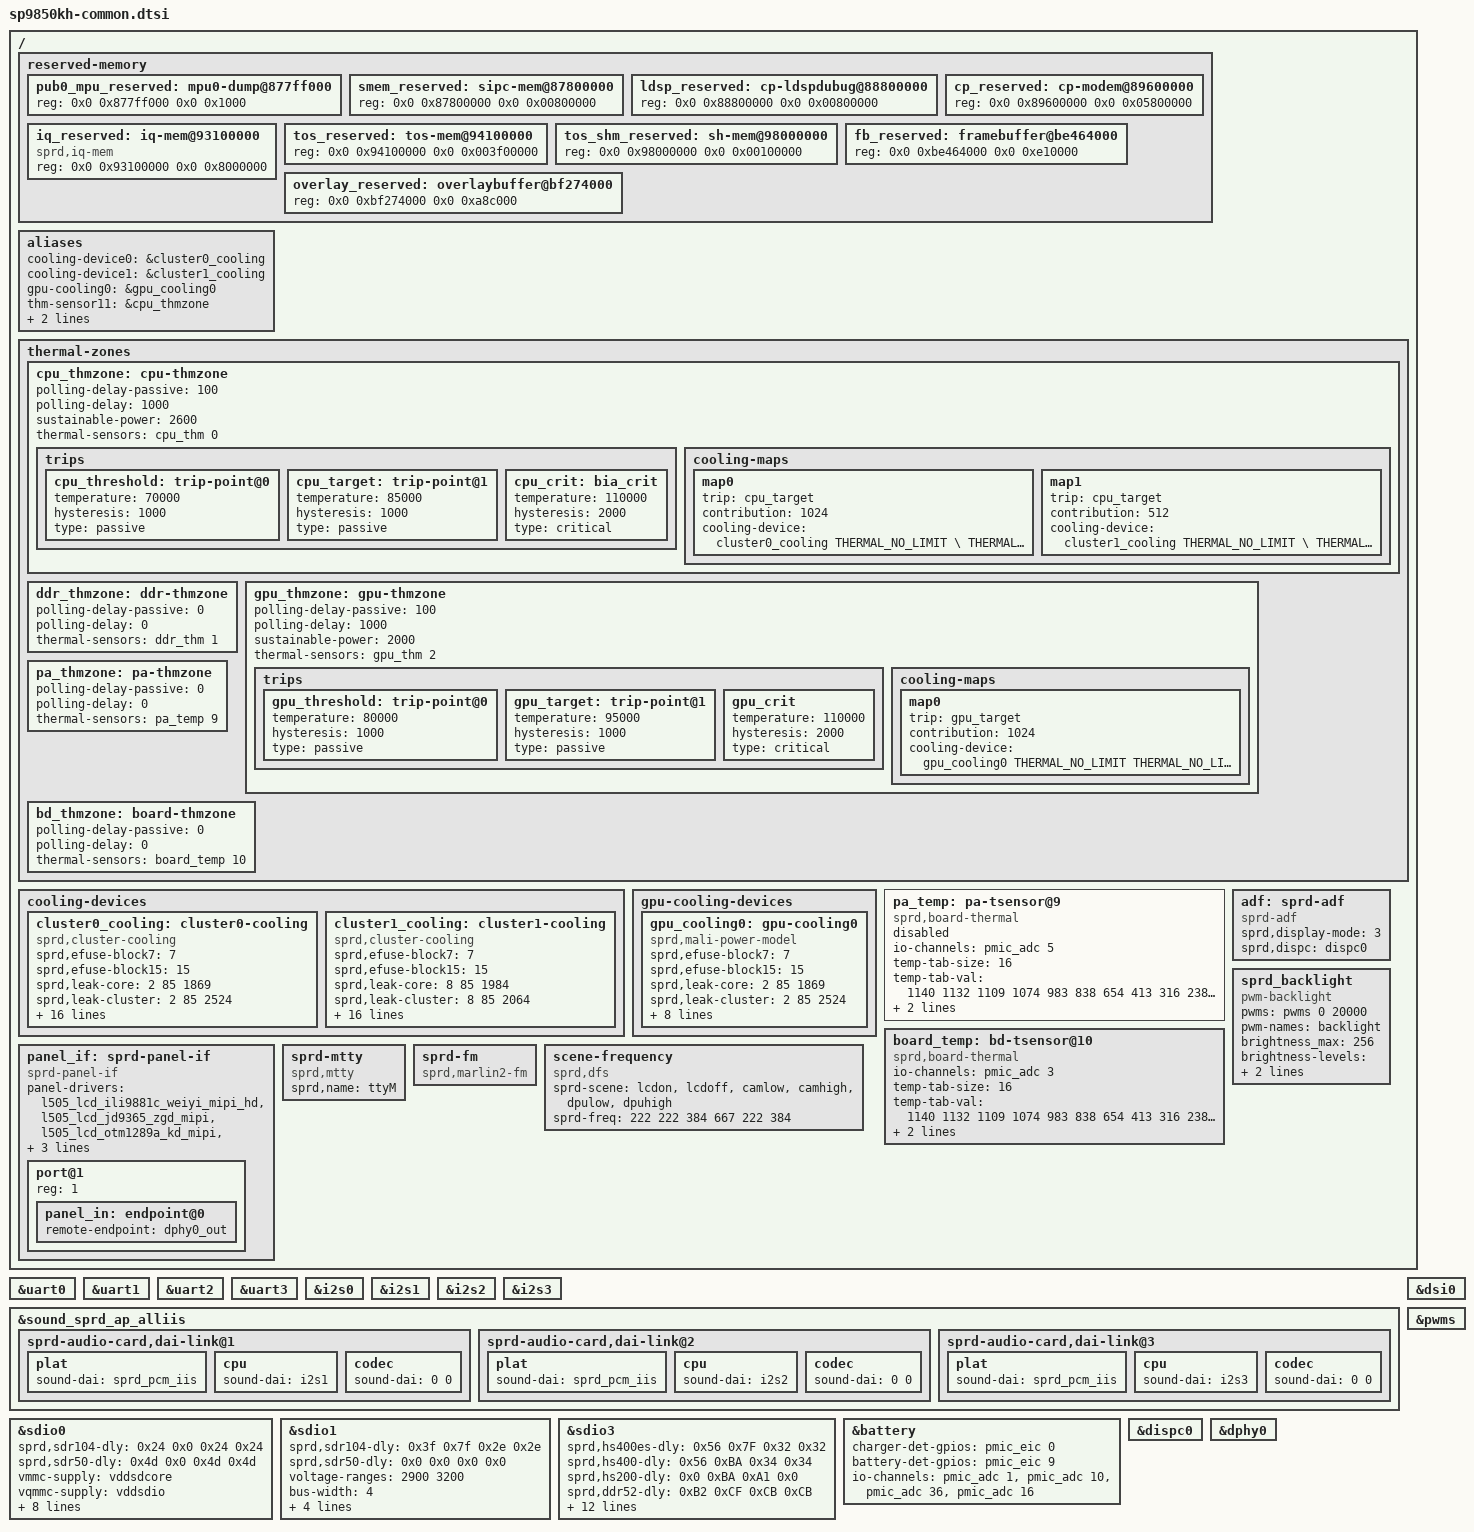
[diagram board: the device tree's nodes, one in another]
/*
 * Spreadtrum SP9850KH board common DTS file
 *
 * Copyright (C) 2016, Spreadtrum Communications Inc.
 *
 * This file is licensed under a dual GPLv2 or X11 license.
 */
#include "lcd/lcd_nt35597_mipi_2k_fpga.dtsi"
#include "lcd/lcd_ili9881c_mipi_hd.dtsi"
#include "lcd/lcd_dummy_rgb.dtsi"
#include "lcd/l505_lcd_ili9881c_weiyi_mipi_hd.dtsi"
#include "lcd/l505_lcd_jd9365_hf_mipi.dtsi"
#include "lcd/l505_lcd_jd9365_zgd_mipi.dtsi"
#include "lcd/l505_lcd_otm1289a_kd_mipi.dtsi"
#include "sc2721.dtsi"
#include "sprd-battery.dtsi"
#include "sp9850kh-modem.dtsi"
#include <dt-bindings/thermal/thermal.h>
#include "sprd-sound-sharkl.dtsi"

/ {
	reserved-memory {
		#address-cells = <2>;
		#size-cells = <2>;
		ranges;

		pub0_mpu_reserved: mpu0-dump@877ff000 {
			reg = <0x0 0x877ff000 0x0 0x1000>;
		};

		smem_reserved: sipc-mem@87800000{
			reg = <0x0 0x87800000 0x0 0x00800000>;
		};

		ldsp_reserved: cp-ldspdubug@88800000 {
			reg = <0x0 0x88800000 0x0 0x00800000>;
		};

		cp_reserved: cp-modem@89600000 {
			reg = <0x0 0x89600000 0x0 0x05800000>;
		};

		/* Only used for iq, will be removed in normal mode by uboot */
		iq_reserved: iq-mem@93100000{
			compatible = "sprd,iq-mem";
			reg = <0x0 0x93100000 0x0 0x8000000>;
		};

		tos_reserved: tos-mem@94100000{
		reg = <0x0 0x94100000 0x0 0x003f00000>;
		};

		tos_shm_reserved: sh-mem@98000000{
			reg = <0x0 0x98000000 0x0 0x00100000>;
		};

		fb_reserved: framebuffer@be464000{
			reg = <0x0 0xbe464000 0x0 0xe10000>;
		};

		overlay_reserved: overlaybuffer@bf274000{
			reg = <0x0 0xbf274000 0x0 0xa8c000>;
		};
	};

	aliases {
		cooling-device0 = &cluster0_cooling;
		cooling-device1 = &cluster1_cooling;
		gpu-cooling0 = &gpu_cooling0;
		thm-sensor11 = &cpu_thmzone;
		thm-sensor9 = &pa_temp;
		thm-sensor10 = &board_temp;
	};

	thermal-zones {

		cpu_thmzone: cpu-thmzone {
			polling-delay-passive = <100>;
			polling-delay = <1000>;
			sustainable-power = <2600>;
			thermal-sensors = <&cpu_thm  0>;
			trips {
				cpu_threshold: trip-point@0 {
					temperature = <70000>;
					hysteresis = <1000>;
					type = "passive";
				};
				cpu_target: trip-point@1 {
					temperature = <85000>;
					hysteresis = <1000>;
					type = "passive";
				};
				cpu_crit: bia_crit {
					temperature = <110000>;
					hysteresis = <2000>;
					type = "critical";
				};
			};
			cooling-maps {
				map0 {
					trip = <&cpu_target>;
					contribution = <1024>;
					cooling-device =
					<&cluster0_cooling THERMAL_NO_LIMIT \
					THERMAL_NO_LIMIT>;
				};
				map1 {
					trip = <&cpu_target>;
					contribution = <512>;
					cooling-device =
					<&cluster1_cooling THERMAL_NO_LIMIT \
					THERMAL_NO_LIMIT>;
				};
			};
		};

		ddr_thmzone: ddr-thmzone {
			polling-delay-passive = <0>;
			polling-delay = <0>;
			thermal-sensors = <&ddr_thm  1>;
		};

		gpu_thmzone: gpu-thmzone {
			polling-delay-passive = <100>;
			polling-delay = <1000>;
			sustainable-power = <2000>;
			thermal-sensors = <&gpu_thm  2>;
			trips {
				gpu_threshold: trip-point@0 {
					temperature = <80000>;
					hysteresis = <1000>;
					type = "passive";
				};
				gpu_target: trip-point@1 {
					temperature = <95000>;
					hysteresis = <1000>;
					type = "passive";
				};
				gpu_crit: gpu_crit {
					temperature = <110000>;
					hysteresis = <2000>;
					type = "critical";
				};
			};
			cooling-maps {
				map0 {
					trip = <&gpu_target>;
					contribution = <1024>;
					cooling-device =
					<&gpu_cooling0
						THERMAL_NO_LIMIT
						THERMAL_NO_LIMIT>;
				};
			};
		};

		pa_thmzone: pa-thmzone {
			polling-delay-passive = <0>;
			polling-delay = <0>;
			thermal-sensors = <&pa_temp  9>;
		};

		bd_thmzone: board-thmzone {
			polling-delay-passive = <0>;
			polling-delay = <0>;
			thermal-sensors = <&board_temp  10>;
		};
	};

	cooling-devices {
		cluster0_cooling: cluster0-cooling {
			compatible = "sprd,cluster-cooling";
			#cooling-cells = <2>; /* min followed by max */
			sprd,efuse-block7 = <7>;
			sprd,efuse-block15 = <15>;
			/* core_leak =                             */
			/*(LIT_LEAK[4:0]+1) x 2mA x 0.85V x 18.69% */
			sprd,leak-core = <2 85 1869>;
			/* cluster_leak =                           */
			/* (LIT_LEAK[4:0]+1) x 2mA x 0.85V x 25.24% */
			sprd,leak-cluster = <2 85 2524>;
			/*core Tscale = aT^3 + bT^2 + cT +di   */
			sprd,core-temp-scale =
			/* a*10^7   b*10^7      c*10^7     d*10^7 */
			<  300      (-28000)   1469000    (-13944000)>;
			/*core Vscale = eV^3 + fV^2 + gV + h */
			sprd,core-voltage-scale =
			/* e*10^2   f*10^2     g*10^2  h*10^2*/
			<  2345     (-5487)    4472    (-1231)>;
			/*cluster Tscale = aT^3 + bT^2 + cT +di   */
			sprd,cluster-temp-scale =
			/* a*10^7   b*10^7      c*10^7     d*10^7 */
			<  300      (-28000)   1469000    (-13944000)>;
			/*cluster Vscale = eV^3 + fV^2 + gV + h */
			sprd,cluster-voltage-scale =
			/* e*10^2   f*10^2     g*10^2  h*10^2*/
			<  2345     (-5487)    4472    (-1231)>;
			sprd,efuse-switch = <0>;
			sprd,hotplug-period = <0>;
			sprd,min-cpufreq = <768000>;
			sprd,min-cpunum = <0>;
			sprd,core-base = <864>;
			sprd,cluster-base = <457>;
			sprd,dynamic-core =
			/*Pdynperghz*10    Freq     Vbase  */
			< 1274           1000     1000>;
			sprd,dynamic-cluster =
			/*Pdynperghz*10    Freq     Vbase  */
			< 430           1000     1000>;
		};
		cluster1_cooling: cluster1-cooling {
			compatible = "sprd,cluster-cooling";
			#cooling-cells = <2>; /* min followed by max */
			sprd,efuse-block7 = <7>;
			sprd,efuse-block15 = <15>;
			/* core_leak =                             */
			/*(LIT_LEAK[4:0]+1) x 2mA x 0.85V x 18.69% */
			sprd,leak-core = <8 85 1984>;
			/* cluster_leak =                           */
			/* (LIT_LEAK[4:0]+1) x 2mA x 0.85V x 25.24% */
			sprd,leak-cluster = <8 85 2064>;
			/*core Tscale = aT^3 + bT^2 + cT +d  */
			sprd,core-temp-scale =
			/* a*10^7   b*10^7	c*10^7	   d*10^7*/
			<  300      (-26000)   1352000    (-12227000)>;
			/* core  Vscale = eV^3 + fV^2 + gV + h */
			sprd,core-voltage-scale =
			/* e*10^2  f*10^2     g*10^2  h*10^2*/
			<  2345     (-5487)    4472    (-1231)>;
			/*cluster Tscale = aT^3 + bT^2 + cT +di   */
			sprd,cluster-temp-scale =
			/* a*10^7   b*10^7      c*10^7     d*10^7 */
			<  300      (-26000)   1352000    (-12227000)>;
			/*cluster Vscale = eV^3 + fV^2 + gV + h */
			sprd,cluster-voltage-scale =
			/* e*10^2   f*10^2     g*10^2  h*10^2*/
			<  2345     (-5487)    4472    (-1231)>;
			sprd,efuse-switch = <0>;
			sprd,hotplug-period = <10>;
			sprd,min-cpufreq = <768000>;
			sprd,min-cpunum = <0>;
			sprd,core-base = <1321>;
			sprd,cluster-base = <1214>;
			sprd,dynamic-core =
			/* Pdynperghz*10    Freq     Vbase */
			<  2492          1000     1000>;
			sprd,dynamic-cluster =
			/* Pdynperghz*10    Freq     Vbase */
			<  669           1000     1000>;
		};
	};

	gpu-cooling-devices {
		gpu_cooling0: gpu-cooling0 {
			compatible = "sprd,mali-power-model";
			#cooling-cells = <2>;
			sprd,efuse-block7 = <7>;
			sprd,efuse-block15 = <15>;
			/* core_leak =                             */
			/*(LIT_LEAK[4:0]+1) x 2mA x 0.85V x 18.69% */
			sprd,leak-core = <2 85 1869>;
			/* cluster_leak =                           */
			/* (LIT_LEAK[4:0]+1) x 2mA x 0.85V x 25.24% */
			sprd,leak-cluster = <2 85 2524>;
			/*Tscale = aT^3 + bT^2 + cT +di   */
			sprd,temp-scale =
			/* a*10^7   b*10^7      c*10^7     d*10^7 */
			<  300     (-29000)     1491000    (-13962000)>;
			/*Vscale = eV^3 + fV^2 + gV + h */
			sprd,voltage-scale =
			/* e*10^2   f*10^2     g*10^2      h*10^2*/
			<  (-1629)  6627       (-6871)     2222>;
			sprd,hotplug-period = <0>;
			sprd,core-base = <966>;
			sprd,cluster-base = <966>;
			sprd,dynamic-core =
			/*Pdynperghz    Freq     Vbase  */
			< 6046           768     900>;
			sprd,dynamic-cluster =
			/*Pdynperghz    Freq     Vbase  */
			< 6064           768     900>;
		};
	};

	pa_temp:pa-tsensor@9 {
		compatible = "sprd,board-thermal";
		#thermal-sensor-cells = <1>;
		io-channels = <&pmic_adc 5>;
		io-channel-names = "adc_temp";
		temp-tab-size = <16>;
		temp-tab-val = <1140 1132 1109 1074 983 838 654 413
				316 238 178 133 99 75 57 43>;
		temp-tab-temp = <558 596 704 806 953 1101 1248 1450
				1549 1649 1749 1849 1951 2049 2148 2252>;
	};

	board_temp:bd-tsensor@10 {
		compatible = "sprd,board-thermal";
		#thermal-sensor-cells = <1>;
		io-channels = <&pmic_adc 3>;
		io-channel-names = "adc_temp";
		temp-tab-size = <16>;
		temp-tab-val = <1140 1132 1109 1074 983 838 654 413
				316 238 178 133 99 75 57 43>;
		temp-tab-temp = <558 596 704 806 953 1101 1248 1450
				1549 1649 1749 1849 1951 2049 2148 2252>;
	};

	panel_if: sprd-panel-if {
		compatible = "sprd-panel-if";
		#address-cells = <1>;
		#size-cells = <0>;
		panel-drivers = <
			&l505_lcd_ili9881c_weiyi_mipi_hd
			&l505_lcd_jd9365_zgd_mipi
			&l505_lcd_otm1289a_kd_mipi
			&l505_lcd_jd9365_hf_mipi
			&lcd_ili9881c_mipi_hd
			&lcd_nt35597_mipi_2k_fpga
			&lcd_dummy_rgb
		>;

		/* input port */
		port@1 {
		/* WARNING: the reg property must be 1 ! */
			reg = <1>;
			panel_in: endpoint@0 {
				remote-endpoint = <&dphy0_out>;
			};
		};
	};

	adf: sprd-adf {
		compatible = "sprd-adf";
		status = "okay";
		sprd,display-mode = <3>;
		sprd,dispc = <&dispc0>;
	};

	sprd_backlight {
		compatible = "pwm-backlight";
		pwms = <&pwms 0 20000>;
		pwm-names = "backlight";
		brightness_max = <256>;
		brightness-levels = <
						6   6   6   6
			6   6   6   6   6   6   6   7   8   9
			10  11  12  13  14  15  16  17  18  19
			20  21  22  23  24  25  26  27  28  29
			30  31  32  33  34  35  36  37  38  39
			40  41  42  43  44  45  46  47  48  49
			50  51  52  53  54  55  56  57  58  59
			60  61  62  63  64  65  66  67  68  69
			70  71  72  73  74  75  76  77  78  79
			80  81  82  83  84  85  86  87  88  89
			90  91  92  93  94  95  96  97  98  99
			100 101 102 103 104 105 106 107 108 109
			110 111 112 113 114 115 116 117 118 119
			120 121 122 123 124 125 126 127 128 129
			130 131 132 133 134 135 136 137 138 139
			140 141 142 143 144 145 146 147 148 149
			150 151 152 153 154 155 156 157 158 159
			160 161 162 163 164 165 166 167 168 169
			170 171 172 173 174 175 176 177 178 179
			180 181 182 183 184 185 186 187 188 189
			190 191 192 193 194 195 196 197 198 199
			200 201 202 203 204 205 206 207 208 209
			210 211 212 213 214 215 216 217 218 219
			220 221 222 223 224 225 226 227 228 229
			230 231 232 233 234 235 236 237 238 239
			240 241 242 243 244 245 246 247 248 249
			250 251
			>;
		default-brightness-level = <25>;
	};

	sprd-mtty {
		compatible = "sprd,mtty";
		sprd,name = "ttyM";
	};

	sprd-fm {
		compatible  = "sprd,marlin2-fm";
	};

	scene-frequency {
		compatible = "sprd,dfs";
		sprd-scene = "lcdon", "lcdoff", "camlow",
			"camhigh", "dpulow", "dpuhigh";
		sprd-freq = <222 222 384 667 222 384>;
	};
};

&uart0 {
	status = "okay";
};

&uart1 {
	status = "okay";
};

&uart2 {
	status = "okay";
};

&uart3 {
	status = "okay";
};

&i2s0 {
	status = "okay";
};

&i2s1 {
	status = "okay";
};

&i2s2 {
	status = "okay";
};

&i2s3 {
	status = "okay";
};

&sound_sprd_ap_alliis {
	sprd-audio-card,dai-link@1 {
		plat {
			sound-dai = <&sprd_pcm_iis>;
		};
		cpu {
			sound-dai = <&i2s1>;
		};
		codec {
			sound-dai = <0 0>;
		};
	};
	sprd-audio-card,dai-link@2 {
		plat {
			sound-dai = <&sprd_pcm_iis>;
		};
		cpu {
			sound-dai = <&i2s2>;
		};
		codec {
			sound-dai = <0 0>;
		};
	};
	sprd-audio-card,dai-link@3 {
		plat {
			sound-dai = <&sprd_pcm_iis>;
		};
		cpu {
			sound-dai = <&i2s3>;
		};
		codec {
			sound-dai = <0 0>;
		};
	};
};

&sdio0 {
	sprd,sdr104-dly = <0x24 0x0 0x24 0x24>;
	sprd,sdr50-dly = <0x4d 0x0 0x4d 0x4d>;
	vmmc-supply = <&vddsdcore>;
	vqmmc-supply = <&vddsdio>;
	voltage-ranges = <3000 3000>;
	bus-width = <4>;
	sd-uhs-sdr50;
	sprd,name = "sdio_sd";
	no-sdio;
	no-mmc;
	pinctrl-names = "sd0_ms_0","sd0_ms_1";
	pinctrl-0 = <&vio_sd0_ms_0>;
	pinctrl-1 = <&vio_sd0_ms_1>;
	status = "okay";
};

&sdio1 {
	sprd,sdr104-dly = <0x3f 0x7f 0x2e 0x2e>;
	sprd,sdr50-dly = <0x0 0x0 0x0 0x0>;
	voltage-ranges = <2900 3200>;
	bus-width = <4>;
	sprd,name = "sdio_wifi";
	no-sd;
	no-mmc;
	keep-power-in-suspend;
	status = "okay";
};

&sdio3 {
	sprd,hs400es-dly = <0x56 0x7F 0x32 0x32>;
	sprd,hs400-dly = <0x56 0xBA 0x34 0x34>;
	sprd,hs200-dly = <0x0 0xBA 0xA1 0x0>;
	sprd,ddr52-dly = <0xB2 0xCF 0xCB 0xCB>;
	vmmc-supply = <&vddemmccore>;
	voltage-ranges = <3000 3000>;
	bus-width = <8>;
	non-removable;
	cap-mmc-hw-reset;
	mmc-hs400-enhanced-strobe;
	mmc-hs400-1_8v;
	mmc-hs200-1_8v;
	mmc-ddr-1_8v;
	sprd,name = "sdio_emmc";
	no-sdio;
	no-sd;
	status = "okay";
};

&battery {
	charger-det-gpios = <&pmic_eic 0 0>;
	battery-det-gpios = <&pmic_eic 9 0>;
	io-channels = <&pmic_adc 1>,<&pmic_adc 10>,
			<&pmic_adc 36>,<&pmic_adc 16>;
	io-channel-names = "adc_temp","adc_vbat",
			"adc_vchg","adc_isense";
	status = "okay";
};

&dispc0 {
	status = "okay";
};

&dsi0 {
	status = "okay";
};

&dphy0 {
	status = "okay";
};

&pwms {
	status = "okay";
};

&pa_temp {
	status = "disabled";
};
